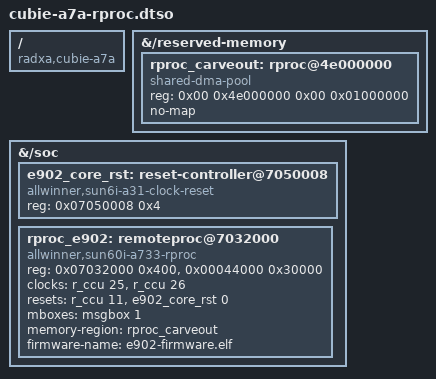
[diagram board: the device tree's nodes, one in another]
/dts-v1/;
/plugin/;

/*
 * ============================================================================
 *               RADXA CUBIE A7A — XUANTIE E902 REMOTEPROC OVERLAY
 * ============================================================================
 * Enables the XuanTie E902 32-bit RISC-V coprocessor (RV32EMC @ 200 MHz)
 * running under Linux RemoteProc (Mode 2: Real-Time Coprocessor).
 *
 * Memory Regions:
 *   - System SRAM A2: 0x00044000 (192 KB) firmware window; host 0x00040000-0x00043FFF is the
 *     16 KB CPUS-only part (A733 User Manual memory map), not used
 *   - DMA Carveout:   0x4E000000 (16 MB) shared DRAM vdev/virtio buffer pool
 *
 * Hardware Lifecycle Controls:
 *   - CFG & Vector:   0x07032000 (E902_CFG, entry vector @ +0x204)
 *   - Clocks:         r_ccu CLK_BUS_R_RISCV (core), CLK_BUS_R_RISCV_CFG (bus)
 *                     (RISCV_BGR_REG 0x0721C bits 0 and 1)
 *   - Resets:         r_ccu RST_BUS_R_RISCV_CFG = "cfg" (E902_CFG block; it ignores
 *                     writes while held), R_CPUCFG 0x07050008 bit 0 = "core"
 *                     (core run, active-low). Order and registers from the vendor
 *                     BL31 arisc start; see CUBIE_A7A_E902_REBUILD_GUIDE.md 6.1.
 *   - E902 view:      SRAM A2 host 0x00044000 = E902 0x40004000; DRAM 1:1 from 0x40034000
 *   - Mailbox:        msgbox (@ 0x03004000 / 0x07094000)
 * ============================================================================
 */

/ {
	compatible = "radxa,cubie-a7a", "allwinner,sun60i-a733";

	fragment@0 {
		target-path = "/reserved-memory";
		__overlay__ {
			#address-cells = <2>;
			#size-cells = <2>;

			rproc_carveout: rproc@4e000000 {
				compatible = "shared-dma-pool";
				reg = <0x00 0x4e000000 0x00 0x01000000>; /* 16 MB pool */
				no-map;
			};
		};
	};

	fragment@1 {
		target-path = "/soc";
		__overlay__ {
			/* E902 core reset: R_CPUCFG 0x07050008 bit 0, 1 = running */
			e902_core_rst: reset-controller@7050008 {
				compatible = "allwinner,sun6i-a31-clock-reset";
				reg = <0x07050008 0x4>;
				#reset-cells = <1>;
			};

			rproc_e902: remoteproc@7032000 {
				compatible = "allwinner,sun60i-a733-rproc";
				reg = <0x07032000 0x400>,
				      <0x00044000 0x30000>;
				reg-names = "cfg", "sram";
				/* IDs from dt-bindings/clock/allwinner,sun60i-a733-r-ccu.h */
				clocks = <&r_ccu 25>,  /* CLK_BUS_R_RISCV */
				         <&r_ccu 26>;  /* CLK_BUS_R_RISCV_CFG */
				clock-names = "core", "bus";
				resets = <&r_ccu 11>,          /* RST_BUS_R_RISCV_CFG: E902_CFG block */
				         <&e902_core_rst 0>;   /* R_CPUCFG 0x07050008 bit 0: core */
				reset-names = "cfg", "core";
				mboxes = <&msgbox 1>;	/* route 0 (E902), port 1: the firmware rings Channel1 (A5E: <&msgbox 9>) */
				memory-region = <&rproc_carveout>;
				firmware-name = "e902-firmware.elf";
				status = "okay";
			};
		};
	};
};
